# QEMU_VIRT register map
File version: 1.0
The devices of QEMU's virt machine for RISC-V that the e2e program uses.
Registers are 32-bit, read-write, no defined reset value unless marked. A register's access mark holds for its fields unless they carry their own. Offsets are from the block's base; lines under a group give offsets from that group; [hi:lo] are bit positions; {n}, {i} and the like mark numbered series; 'fields as' and 'values as' point back to an identical list; <NAME> marks a mode.

## Memory map
0x00100000 TEST — The test finisher: writing to it stops QEMU.
0x0C000000 PLIC — The platform-level interrupt controller.
0x0C200000 PLIC_M0 — The machine mode context of the PLIC alone: a second view of bytes PLIC covers.
0x10000000 UART0 — The 16550 UART: the console of the machine.
{0x10001000+0x1000*n} VIRTIO{n} (n=0..7) — A virtio-mmio transport: eight of them, one type.

## UART0 — The 16550 UART: the console of the machine.
Base 0x10000000
0x00 RBR 8-bit ro — Receiver buffer: the byte received, when the divisor latch is closed.
0x00 THR 8-bit wo — Transmitter holding register: the byte to send, when the divisor latch is closed.
0x00 DLL 8-bit (DLAB view) — Divisor latch, low byte: at the offset of RBR and THR while LCR.DLAB is set.
0x01 DLM 8-bit (DLAB view) — Divisor latch, high byte: at the offset of IER while LCR.DLAB is set.
0x01 IER 8-bit — Interrupt enable: one bit per cause of interrupt, all off at reset.
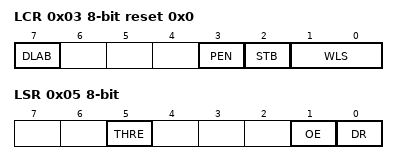
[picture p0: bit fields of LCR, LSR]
0x03 LCR 8-bit reset 0x0 — Line control: the format of a word and the divisor latch.
  [7] DLAB — Divisor latch access: DLL and DLM replace RBR, THR and IER.
  [3] PEN — Parity enabled.
  [2] STB — Two stop bits instead of one.
  [1:0] WLS — Word length.
    0=FIVE (5 bits.); 1=SIX (6 bits.); 2=SEVEN (7 bits.); 3=EIGHT (8 bits.)
0x05 LSR 8-bit ro — Line status.
  [5] THRE — THR is empty: it takes a byte.
  [1] OE read-clears — Overrun error: a byte was lost. Reading the register clears it.
  [0] DR — Data ready: a byte waits in RBR.

## TEST — The test finisher: writing to it stops QEMU.
Base 0x00100000
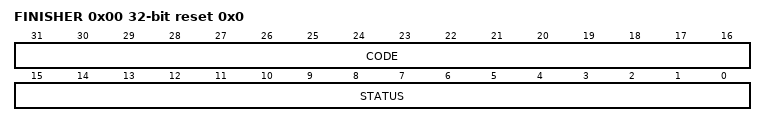
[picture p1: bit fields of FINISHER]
0x00 FINISHER wo reset 0x0 (reset mask 0xFFFF0000) — What to stop with.
  [31:16] CODE — The exit code of a failure.
  [15:0] STATUS — How the machine stops.
    0x3333=FAIL (Stops with failure, the exit code being CODE.); 0x5555=PASS (Stops with success.)

## PLIC — The platform-level interrupt controller.
Base 0x0C000000
{0x0+4i} PRIORITY[{i}] (i=0..95) — The priority of each source; QEMU keeps 3 bits.
{0x1000+4i} PENDING[{i}] (i=0..2) ro — Pending bits, 32 sources a word.
{0x200000+0x1000*i} CTX[{i}] (i=0..1) group — One context of hart 0: machine mode, then supervisor mode.
  0x00 THRESHOLD — The lowest priority the context takes.
  0x04 CLAIM read-modifies — Reading it takes the interrupt it names.

## PLIC_M0 — The machine mode context of the PLIC alone: a second view of bytes PLIC covers.
Base 0x0C200000
0x00 THRESHOLD — The lowest priority the context takes.
0x04 CLAIM read-modifies — Reading it takes the interrupt it names.

## VIRTIO{n} — A virtio-mmio transport: eight of them, one type.
Base 0x10001000; array of 8, step 0x1000
0x00 MAGIC_VALUE ro — "virt" in ASCII.
0x04 VERSION ro — The version of the transport: 1 is the legacy one.
0x08 DEVICE_ID ro — The kind of device attached, 0 for none.
0x0C VENDOR_ID ro — "QEMU" in ASCII.
